# SC32F12XRX48 register map
File version: 1.0
CPU: CM0+ r0p1, little endian, MPU, no FPU, 4 interrupt priority bits
Registers are 32-bit, read-write, reset 0x0 unless marked. A register's access mark holds for its fields unless they carry their own. Offsets are from the block's base; [hi:lo] are bit positions; {n}, {i} and the like mark numbered series.

## IAP
Base 0x400003C0
0x00 IAP_KEY
  [31:0] IAPKEY — Save the data
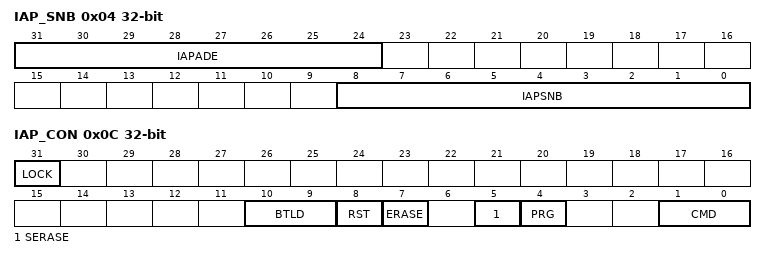
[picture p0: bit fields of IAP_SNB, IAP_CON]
0x04 IAP_SNB — IAP Sector number register
  [31:24] IAPADE — IAP Address
  [8:0] IAPSNB — IAP Sector number
0x0C IAP_CON — IAP Control register
  [31] LOCK — IAP LOCK
  [10:9] BTLD — IAP BTLD
  [8] RST — IAP Software reset
  [7] ERASE — IAP ALL ERASE
  [5] SERASE — IAP Sector ERASE
  [4] PRG — IAP programming
  [1:0] CMD — IAP command

## CRC — Cyclic redundancy check calculation unit
Base 0x40002000
0x00 DR reset 0xFFFFFFFF — Data register
  [31:0] DR — Data register bits
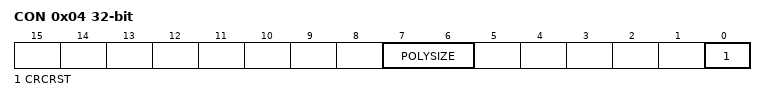
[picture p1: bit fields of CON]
0x04 CON — Control register
  [7:6] POLYSIZE — Controls the size of the polynomials
  [0] CRCRST — register rest bit
0x08 INT reset 0xFFFFFFFF — Initial CRC value
  [31:0] CRC_INIT — Programmable initial CRC value
0x0C POL reset 0x4C11DB7 — polynomial
  [31:0] POL — Programmable polynomial

## RCC_AHB — System configuration controller
Base 0x40003000
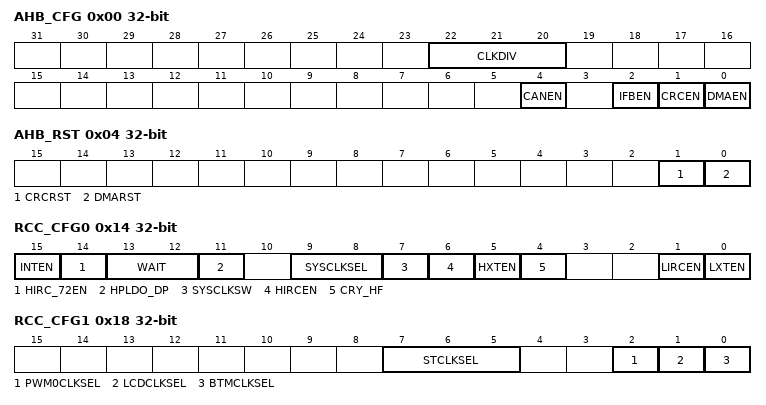
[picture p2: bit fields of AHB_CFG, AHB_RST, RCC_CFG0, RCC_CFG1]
0x00 AHB_CFG — AHB Configuration register
  [22:20] CLKDIV — CLOCK Division
  [4] CANEN — CAN Clock enable
  [2] IFBEN — IFB Clock enable
  [1] CRCEN — CRC Clock enable
  [0] DMAEN — DMA Clock enable
0x04 AHB_RST — AHB Reset register
  [1] CRCRST — CRC RESET
  [0] DMARST — DMA RESET
0x0C RCC_KEY
  [7:0] RCCKEY
0x14 RCC_CFG0 — RCC configuration register 0
  [15] INTEN — Interrput enable
  [14] HIRC_72EN — HIRC 72M enable
  [13:12] WAIT
  [11] HPLDO_DP
  [9:8] SYSCLKSEL — System clock Select
  [7] SYSCLKSW — System clock swtich
  [6] HIRCEN — HIRC enable
  [5] HXTEN — HXT enable
  [4] CRY_HF — External crystal oscillator frequency
  [1] LIRCEN — LIRC enable
  [0] LXTEN — LXT enable
0x18 RCC_CFG1 — RCC configuration register 1
  [7:5] STCLKSEL — Systick clock select
  [2] PWM0CLKSEL — PWM0 clock select
  [1] LCDCLKSEL — LCD clock select
  [0] BTMCLKSEL — BTM clock select
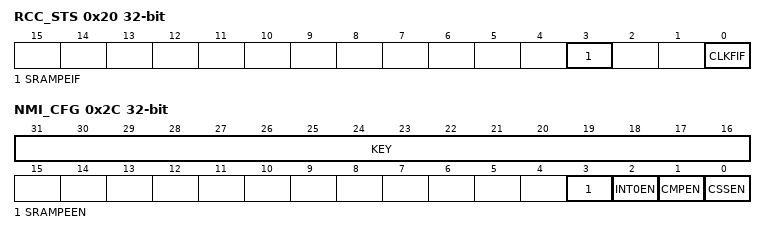
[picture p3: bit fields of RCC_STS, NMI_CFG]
0x20 RCC_STS — RCC status register
  [3] SRAMPEIF — SRAM fail flag
  [0] CLKFIF — Clock fail flag
0x28 SYST_CALIB ro — Systick register
  [7:0] CALIB — Calibrate register defaults
0x2C NMI_CFG — NMI Config register
  [31:16] KEY — NMI KEY
  [3] SRAMPEEN — SRAMPE enable
  [2] INT0EN — Interrupt 0 enable
  [1] CMPEN — Comparator enable
  [0] CSSEN — Clock safety system enable

## RCC_APB0 — System configuration controller
Base 0x40020000
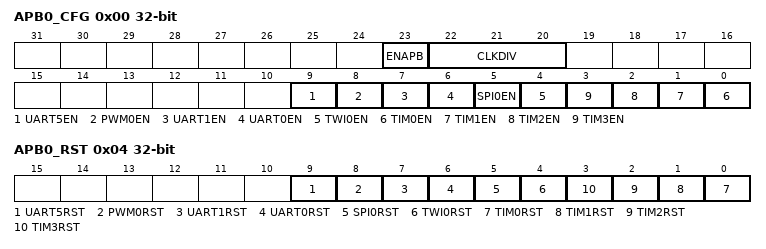
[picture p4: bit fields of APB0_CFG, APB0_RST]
0x00 APB0_CFG — APB0 Configuration register
  [23] ENAPB — APB Clock enable
  [22:20] CLKDIV — CLOCK division enable
  [9] UART5EN — UART5 enable
  [8] PWM0EN — PWM0 enable
  [7] UART1EN — UART1 enable
  [6] UART0EN — UART0 enable
  [5] SPI0EN — SPI0 enable
  [4] TWI0EN — TWI0 enable
  [n] TIM{n}EN (n=0..3) — TIM{n} enable
0x04 APB0_RST — APB0 Reset register
  [9] UART5RST — UART5 Reset
  [8] PWM0RST — PWM0 Reset
  [7] UART1RST — UART1 Reset
  [6] UART0RST — UART0 Reset
  [5] SPI0RST — SPI0 Reset
  [4] TWI0RST — TWI0 Reset
  [n] TIM{n}RST (n=0..3) — TIM{n} Reset

## RCC_APB1 — System configuration controller
Base 0x40021000
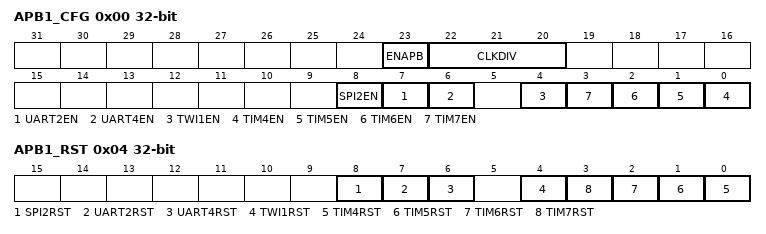
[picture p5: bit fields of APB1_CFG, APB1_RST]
0x00 APB1_CFG — APB1 Configuration register
  [23] ENAPB — APB Colck enable
  [22:20] CLKDIV
  [8] SPI2EN
  [7] UART2EN
  [6] UART4EN
  [4] TWI1EN
  [n-4] TIM{n}EN (n=4..7)
0x04 APB1_RST — APB1 Configuration register
  [8] SPI2RST — SPI2 Reset
  [7] UART2RST — UART2 Reset
  [6] UART4RST — UART4 Reset
  [4] TWI1RST — TWI1 Reset
  [n-4] TIM{n}RST (n=4..7) — TIM{n} Reset

## RCC_APB2 — System configuration controller
Base 0x40022000
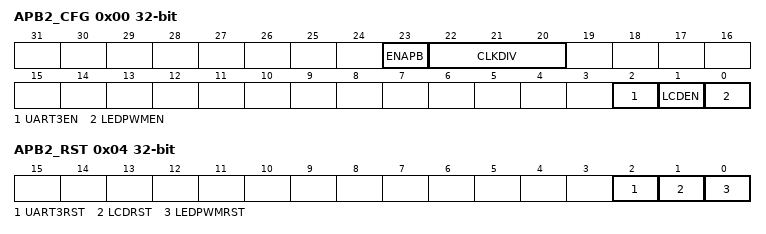
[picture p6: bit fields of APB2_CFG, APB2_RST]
0x00 APB2_CFG — APB2 Configuration register
  [23] ENAPB — APB2 Clock enable
  [22:20] CLKDIV — APB2 Clock Divsion enable
  [2] UART3EN — UART3 Clock enable
  [1] LCDEN — LCD Clock enable
  [0] LEDPWMEN — LEDPWM Clock enable
0x04 APB2_RST — APB2 Configuration register
  [2] UART3RST — UART3 Reset
  [1] LCDRST — LCD Reset
  [0] LEDPWMRST — LEDPWM Reset
